# earlgrey register map
Vendor: lowRISC; File version: 0.1
CPU: ibex rev01, little endian, no MPU, no FPU, VTOR, 2 interrupt priority bits, 2 interrupts
Registers are 32-bit, read-write, no defined reset value unless marked. A register's access mark holds for its fields unless they carry their own. Offsets are from the block's base; [hi:lo] are bit positions.

## RV_TIMER — Memory-mapped timer unit implementing RISC-V mtime and mtimecmp registers
Base 0x40100000
0x40 CTRL — Control register
  [0] active_0 — If 1, timer operates
0x100 INTR_ENABLE0 — Interrupt Enable
  [0] IE_0 — Interrupt Enable for timer
0x104 INTR_STATE0 — Interrupt Status
  [0] IS_0 — Interrupt status for timer
0x108 INTR_TEST0 wo — Interrupt test register
  [0] T_0 — Interrupt test for timer
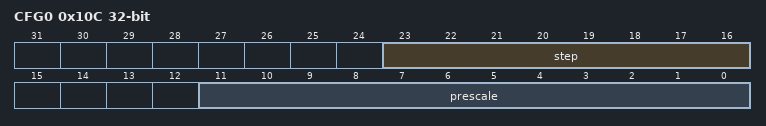
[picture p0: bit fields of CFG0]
0x10C CFG0 — Configuration for Hart 0
  [23:16] step — Incremental value for each tick
  [11:0] prescale — Prescaler to generate tick
0x110 TIMER_V_LOWER0 — Timer value Lower
  [31:0] v — Timer value [31:0]
0x114 TIMER_V_UPPER0 — Timer value Upper
  [31:0] v — Timer value [63:32]
0x118 COMPARE_LOWER0_0 — Timer value Lower
  [31:0] v — Timer compare value [31:0]
0x11C COMPARE_UPPER0_0 — Timer value Upper
  [31:0] v — Timer compare value [63:32]

## RSTMGR_AON — Controls the on-chip reset signals, records reset cause and CPU crash dump for software
Base 0x40410000
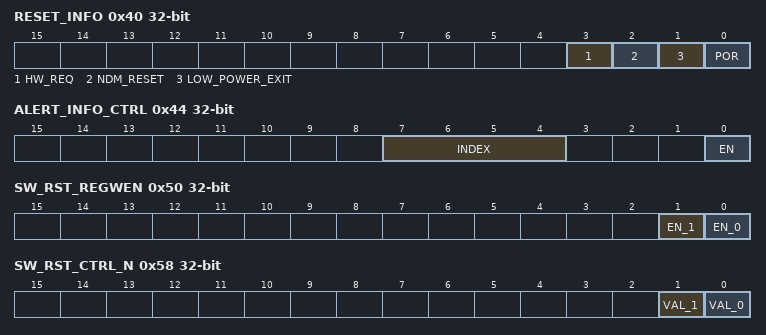
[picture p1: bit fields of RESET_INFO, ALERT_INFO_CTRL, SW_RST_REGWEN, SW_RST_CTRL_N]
0x40 RESET_INFO — Device reset reason.
  [3] HW_REQ — Indicates when a device has reset due to a peripheral request.This can be an alert escalation, watchdog or anything else.
  [2] NDM_RESET — Indicates when a device has reset due to non-debug-module request.
  [1] LOW_POWER_EXIT — Indicates when a device has reset due low power exit.
  [0] POR — Indicates when a device has reset due to power up.
0x44 ALERT_INFO_CTRL — Alert info dump controls.
  [7:4] INDEX — Controls which 32-bit value to read.
  [0] EN — Enable alert dump to capture new information.This field is automatically set to 0 upon system reset (even if rstmgr is not reset).
0x48 ALERT_INFO_ATTR ro — Alert info dump attributes.
  [3:0] CNT_AVAIL — The number of 32-bit values contained in the alert info dump.
0x4C ALERT_INFO ro — Alert dump information prior to last reset. Which value read is controlled by the !!ALERT_INFO_CTRL register.
  [31:0] VALUE — The current 32-bit value of alert crash dump.
0x50 SW_RST_REGWEN — Register write enable for software controllable resets.When a particular bit value is 0, the corresponding value in !!SW_RST_CTRL_N can no longer be changed.When a particular bit value is 1, the corresponding value in !!SW_RST_CTRL_N can be changed.
  [1] EN_1 — Register write enable for software controllable resets
  [0] EN_0 — Register write enable for software controllable resets
0x58 SW_RST_CTRL_N — Software controllable resets.When a particular bit value is 0, the corresponding module is held in reset.When a particular bit value is 1, the corresponding module is not held in reset.
  [1] VAL_1 — Software reset value
  [0] VAL_0 — Software reset value

## CLKMGR_AON — Derives and monitors on-chip clock signals, handles clock gating requests from power manager and software
Base 0x40420000
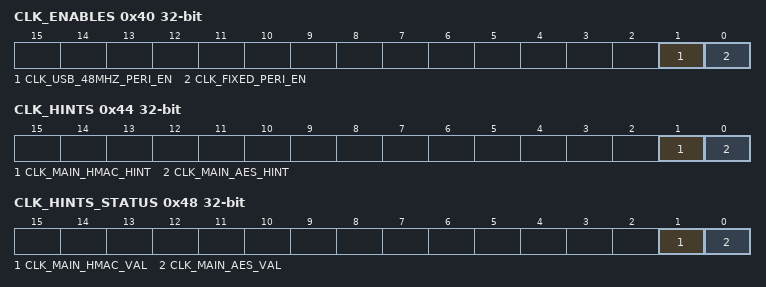
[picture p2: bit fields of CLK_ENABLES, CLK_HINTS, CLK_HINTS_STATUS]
0x40 CLK_ENABLES — Clock enable for software gateable clocks.These clocks are direclty controlled by software.
  [1] CLK_USB_48MHZ_PERI_EN — 0 CLK_USB_48MHZ_PERI is disabled.1 CLK_USB_48MHZ_PERI is enabled.
  [0] CLK_FIXED_PERI_EN — 0 CLK_FIXED_PERI is disabled.1 CLK_FIXED_PERI is enabled.
0x44 CLK_HINTS — Clock hint for software gateable clocks.These clocks are not fully controlled by software.For disable, software only provides a hint, and hardware determines the final clock state based on thehint and whether the block in question is idle.
  [1] CLK_MAIN_HMAC_HINT — 0 CLK_MAIN_HMAC can be disabled.1 CLK_MAIN_HMAC is enabled.
  [0] CLK_MAIN_AES_HINT — 0 CLK_MAIN_AES can be disabled.1 CLK_MAIN_AES is enabled.
0x48 CLK_HINTS_STATUS ro — Since the final state of !!CLK_HINTS is not always determined by software,this register provides read feedback for the current clock state.
  [1] CLK_MAIN_HMAC_VAL — 0 CLK_MAIN_HMAC is disabled.1 CLK_MAIN_HMAC is enabled.
  [0] CLK_MAIN_AES_VAL — 0 CLK_MAIN_AES is disabled.1 CLK_MAIN_AES is enabled.
